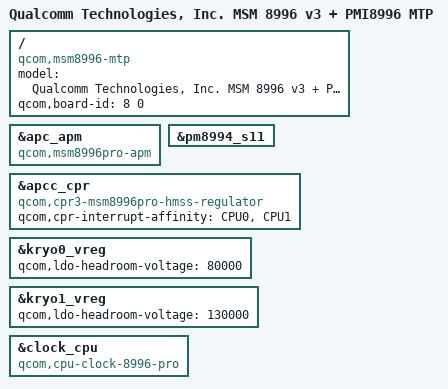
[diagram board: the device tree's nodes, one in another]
/* Copyright (c) 2015, The Linux Foundation. All rights reserved.
 *
 * This program is free software; you can redistribute it and/or modify
 * it under the terms of the GNU General Public License version 2 and
 * only version 2 as published by the Free Software Foundation.
 *
 * This program is distributed in the hope that it will be useful,
 * but WITHOUT ANY WARRANTY; without even the implied warranty of
 * MERCHANTABILITY or FITNESS FOR A PARTICULAR PURPOSE.  See the
 * GNU General Public License for more details.
 */


/dts-v1/;

#include "msm8996-v3.dtsi"
#include "msm-pmi8996.dtsi"
#include "msm8996-mtp.dtsi"

/ {
	model = "Qualcomm Technologies, Inc. MSM 8996 v3 + PMI8996 MTP";
	compatible = "qcom,msm8996-mtp", "qcom,msm8996", "qcom,mtp";
	qcom,board-id = <8 0>;
	};

&apc_apm {
	compatible = "qcom,msm8996pro-apm";
	/delete-property/ qcom,clock-source-override;
};

&pm8994_s11 {
	/delete-property/ qcom,recal-mask;
};

&apcc_cpr {
	compatible = "qcom,cpr3-msm8996pro-hmss-regulator";
	qcom,cpr-interrupt-affinity = <&CPU0 &CPU1>;
};

&kryo0_vreg {
	qcom,ldo-headroom-voltage = <80000>;
};

&kryo1_vreg {
	qcom,ldo-headroom-voltage = <130000>;
};

&clock_cpu {
	compatible = "qcom,cpu-clock-8996-pro";
};
